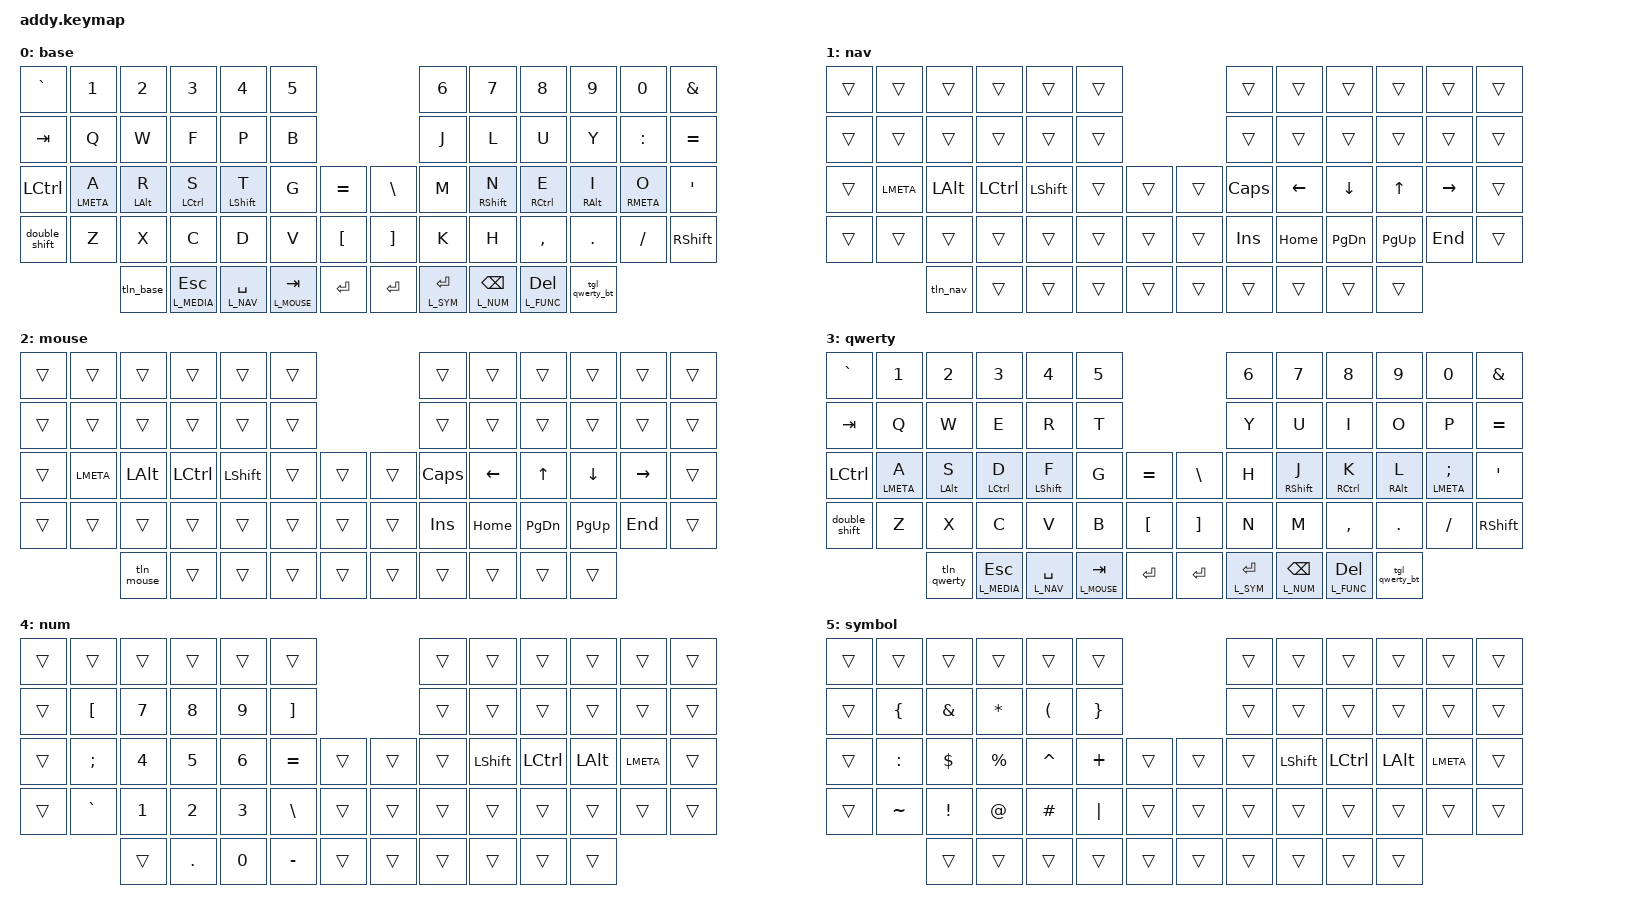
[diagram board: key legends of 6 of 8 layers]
/*
 * Copyright (c) 2020 The ZMK Contributors
 *
 * SPDX-License-Identifier: MIT
 */

#include <behaviors.dtsi>
#include <dt-bindings/zmk/keys.h>
#include <dt-bindings/zmk/bt.h>
#include <dt-bindings/zmk/rgb.h>
#include <dt-bindings/zmk/ext_power.h>
#include <dt-bindings/zmk/outputs.h>

#define L_BASE 0
#define L_NAV 1
#define L_MOUSE 2
#define L_QWERTY 3
#define L_NUM 4
#define L_SYM 5
#define L_FUNC 6
#define L_BT 7
#define L_MEDIA 8


&lt {
    tapping-term-ms = <200>;
    quick-tap-ms = <200>;
};

&mt {
    tapping-term-ms = <300>;
    quick-tap-ms = <200>;
};

/ {
    macros {
        tln_base: type_base {
            label = "Type Base";
            compatible = "zmk,behavior-macro";
            #binding-cells = <0>;
            bindings = <&kp B &kp A &kp S &kp E>;
        };
        tln_nav: type_nav {
            label = "Type nav";
            compatible = "zmk,behavior-macro";
            #binding-cells = <0>;
            bindings = <&kp N &kp A &kp V>;
        };
        tln_mouse: type_mouse {
            label = "Type mouse";
            compatible = "zmk,behavior-macro";
            #binding-cells = <0>;
            bindings = <&kp M &kp O &kp U &kp S &kp E>;
        };
        tln_qwerty: type_qwerty {
            label = "Type qwerty";
            compatible = "zmk,behavior-macro";
            #binding-cells = <0>;
            bindings = <&kp Q &kp W &kp E &kp R &kp T &kp Y>;
        };
    };
};

// colemak macros
#define A_LMETA &mt LMETA A
#define R_LALT  &mt LALT R
#define S_LCTRL &mt LCTRL S
#define T_LSHFT &mt LSHFT T
#define N_RSHFT &mt RSHFT N
#define E_RCTRL &mt RCTRL E
#define I_RALT  &mt RALT I
#define O_RMETA &mt RMETA O

// qwerty versions
// a is the same
#define S_LALT  &mt LALT S
#define D_LCTRL &mt LCTRL D
#define F_LSHFT &mt LSHFT F
#define J_RSHFT &mt RSHFT J
#define K_RCTRL &mt RCTRL K
#define L_RALT  &mt RALT L
#define SEM_LMETA &mt LMETA SEMI


&caps_word {
    continue-list = < UNDERSCORE MINUS >;
};

/ {
    behaviors {
        // toggle qwerty if the K key is tapped twice
        tgl_qwerty_bt: toggle_layer {
            label = "TOG_QWERTY";
            compatible = "zmk,behavior-tap-dance";
            #binding-cells = <0>;
            bindings = < &lt L_BT ESC>, <&tog L_QWERTY >;
        };

        double_shift: double_shift_capsword {
            label = "Double Shift Capsword";
            compatible = "zmk,behavior-tap-dance";
            #binding-cells = <0>;
            bindings = < &kp LSHFT >, < &caps_word >;
        };
    };



    keymap {
        compatible = "zmk,keymap";

        default_layer {
            label = "base";

            bindings = <
             &kp GRAVE      &kp N1       &kp N2       &kp N3           &kp N4          &kp N5                                              &kp N6              &kp N7           &kp N8            &kp N9       &kp N0              &kp AMPERSAND
             &kp TAB        &kp Q        &kp W        &kp F            &kp P           &kp B                                               &kp J               &kp L            &kp U             &kp Y        &kp COLON           &kp EQUAL
             &kp LCTRL      A_LMETA      R_LALT       S_LCTRL          T_LSHFT         &kp G               &kp EQUAL          &kp BSLH     &kp M               N_RSHFT          E_RCTRL           I_RALT       O_RMETA             &kp SQT
             &double_shift  &kp Z        &kp X        &kp C            &kp D           &kp V               &kp LBKT           &kp RBKT     &kp K               &kp H            &kp COMMA         &kp DOT      &kp FSLH            &kp RSHFT
                                         &tln_base    &lt L_MEDIA ESC  &lt L_NAV SPACE &lt L_MOUSE TAB     &kp ENTER          &kp ENTER    &lt L_SYM ENTER     &lt L_NUM  BSPC  &lt L_FUNC DEL    &tgl_qwerty_bt
            >;
        };

        nav_layer {
            label = "nav";
            bindings = <
             &trans       &trans       &trans       &trans       &trans       &trans                                        &trans       &trans       &trans       &trans       &trans       &trans
             &trans       &trans       &trans       &trans       &trans       &trans                                        &trans       &trans       &trans       &trans       &trans       &trans
             &trans       &kp LMETA    &kp LALT     &kp LCTRL    &kp LSHFT    &trans       &trans              &trans       &kp CAPS     &kp LEFT     &kp DOWN     &kp UP       &kp RIGHT    &trans
             &trans       &trans       &trans       &trans       &trans       &trans       &trans              &trans       &kp INS      &kp HOME     &kp PG_DN    &kp PG_UP    &kp END      &trans
                                       &tln_nav     &trans       &trans       &trans       &trans              &trans       &trans       &trans       &trans       &trans
            >;
        };

        mouse_layer {
            label = "mouse";
            bindings = <
             &trans       &trans       &trans       &trans       &trans       &trans                                        &trans       &trans       &trans       &trans       &trans       &trans
             &trans       &trans       &trans       &trans       &trans       &trans                                        &trans       &trans       &trans       &trans       &trans       &trans
             &trans       &kp LMETA    &kp LALT     &kp LCTRL    &kp LSHFT    &trans       &trans              &trans       &kp CAPS     &kp LEFT     &kp UP       &kp DOWN     &kp RIGHT    &trans
             &trans       &trans       &trans       &trans       &trans       &trans       &trans              &trans       &kp INS      &kp HOME     &kp PG_DN    &kp PG_UP    &kp END      &trans
                                       &tln_mouse   &trans       &trans       &trans       &trans              &trans       &trans       &trans       &trans       &trans
            >;
        };

        qwerty {
            label = "qwerty";
            bindings = <
             &kp GRAVE      &kp N1       &kp N2       &kp N3           &kp N4          &kp N5                                             &kp N6              &kp N7           &kp N8           &kp N9         &kp N0        &kp AMPERSAND
             &kp TAB        &kp Q        &kp W        &kp E            &kp R           &kp T                                               &kp Y               &kp U            &kp I            &kp O          &kp P         &kp EQUAL
             &kp LCTRL      A_LMETA      S_LALT       D_LCTRL          F_LSHFT         &kp G              &kp EQUAL          &kp BSLH     &kp H               J_RSHFT          K_RCTRL          L_RALT         SEM_LMETA     &kp SQT
             &double_shift  &kp Z        &kp X        &kp C            &kp V           &kp B              &kp LBKT           &kp RBKT     &kp N               &kp M            &kp COMMA        &kp DOT        &kp SLASH     &kp RSHFT
                                         &tln_qwerty  &lt L_MEDIA ESC  &lt L_NAV SPACE &lt L_MOUSE TAB    &kp ENTER          &kp ENTER    &lt L_SYM ENTER     &lt L_NUM BSPC   &lt L_FUNC DEL   &tgl_qwerty_bt
            >;
        };

        num_layer {
            label = "num";
            bindings = <
             &trans       &trans       &trans       &trans       &trans       &trans                                        &trans       &trans       &trans       &trans       &trans       &trans
             &trans       &kp LBKT     &kp N7       &kp N8       &kp N9       &kp RBKT                                      &trans       &trans       &trans       &trans       &trans       &trans
             &trans       &kp SEMI     &kp N4       &kp N5       &kp N6       &kp EQUAL    &trans              &trans       &trans       &kp LSHFT    &kp LCTRL    &kp LALT     &kp LMETA    &trans
             &trans       &kp GRAVE    &kp N1       &kp N2       &kp N3       &kp BSLH     &trans              &trans       &trans       &trans       &trans       &trans       &trans       &trans
                                       &trans       &kp DOT      &kp N0       &kp MINUS    &trans              &trans       &trans       &trans       &trans       &trans
            >;
        };

        symbol_layer {
            label = "symbol";
            bindings = <
             &trans       &trans       &trans       &trans       &trans       &trans                                          &trans       &trans       &trans       &trans       &trans       &trans
             &trans       &kp LBRC     &kp AMPS     &kp ASTRK    &kp LPAR     &kp RBRC                                        &trans       &trans       &trans       &trans       &trans       &trans
             &trans       &kp COLON    &kp DLLR     &kp PRCNT    &kp CARET    &kp PLUS       &trans              &trans       &trans       &kp LSHFT    &kp LCTRL    &kp LALT     &kp LMETA    &trans
             &trans       &kp TILDE    &kp EXCL     &kp AT       &kp HASH     &kp PIPE       &trans              &trans       &trans       &trans       &trans       &trans       &trans       &trans
                                       &trans       &trans       &trans       &trans         &trans              &trans       &trans       &trans       &trans       &trans
            >;
        };

        function_layer {
            label = "function";
            bindings = <
             &trans       &kp F13    &kp F10      &kp F11      &kp F12      &kp PSCRN                                         &trans       &trans       &trans       &trans       &trans       &trans
             &trans       &kp F12    &kp F7       &kp F8       &kp F9       &kp SLCK         &trans              &trans       &trans       &trans       &trans       &trans       &trans       &trans
             &trans       &kp F11    &kp F4       &kp F5       &kp F6       &kp PAUSE_BREAK  &trans              &trans       &trans       &kp LSHFT    &kp LCTRL    &kp LALT     &kp LMETA    &trans
             &trans       &kp F10    &kp F1       &kp F2       &kp F3       &kp TAB          &trans              &trans       &trans       &trans       &trans       &trans       &trans       &trans
                                     &trans       &trans       &trans       &trans           &trans              &trans       &trans       &trans       &trans       &trans
            >;
        };

        bt_layer {
            label = "bt";
            bindings = <
             &trans       &bt BT_SEL 0 &bt BT_SEL 1 &bt BT_SEL 2 &bt BT_SEL 3 &trans                                        &trans       &trans       &trans       &trans       &trans       &trans
             &trans       &trans       &trans       &trans       &trans       &trans       &trans              &trans       &trans       &trans       &trans       &trans       &trans       &trans
             &trans       &trans       &trans       &trans       &trans       &trans       &trans              &trans       &trans       &trans       &trans       &trans       &trans       &trans
             &trans       &trans       &trans       &trans       &trans       &trans       &trans              &trans       &trans       &trans       &trans       &trans       &trans       &trans
                                       &trans       &trans       &trans       &trans       &trans              &trans       &trans       &bt BT_CLR   &trans       &trans
            >;
        };
    };
};

/*
TRANSPARENT
             &trans       &trans       &trans       &trans       &trans       &trans                                        &trans       &trans       &trans       &trans       &trans       &trans
             &trans       &trans       &trans       &trans       &trans       &trans       &trans              &trans       &trans       &trans       &trans       &trans       &trans       &trans
             &trans       &trans       &trans       &trans       &trans       &trans       &trans              &trans       &trans       &trans       &trans       &trans       &trans       &trans
             &trans       &trans       &trans       &trans       &trans       &trans       &trans              &trans       &trans       &trans       &trans       &trans       &trans       &trans
                                       &trans       &trans       &trans       &trans       &trans              &trans       &trans       &trans       &trans       &trans
*/
